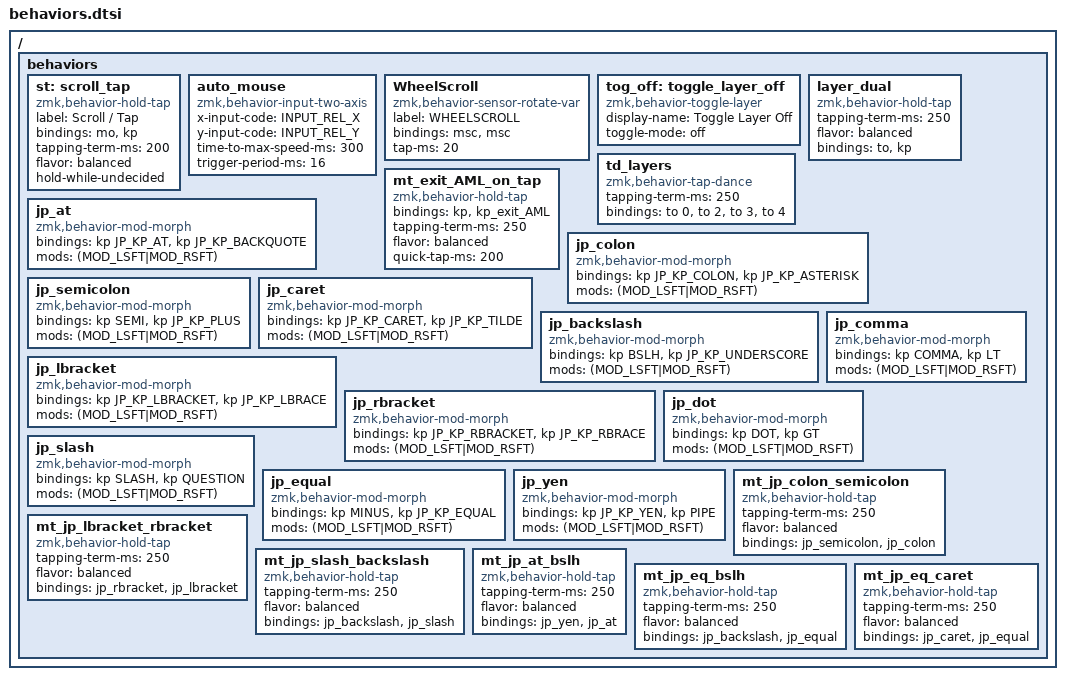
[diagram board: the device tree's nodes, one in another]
#include "JP_KP_defines.h"

/ {
    behaviors {
        st: scroll_tap {
            compatible = "zmk,behavior-hold-tap";
            label = "Scroll / Tap";
            bindings = <&mo>, <&kp>;

            #binding-cells = <2>;
            tapping-term-ms = <200>;
            flavor = "balanced";
            hold-while-undecided;
        };

        auto_mouse: auto_mouse {
            compatible = "zmk,behavior-input-two-axis";
            #binding-cells = <1>;
            x-input-code = <INPUT_REL_X>;
            y-input-code = <INPUT_REL_Y>;
            time-to-max-speed-ms = <300>;
            trigger-period-ms = <16>;
        };

        WheelScroll: WheelScroll {
            compatible = "zmk,behavior-sensor-rotate-var";
            label = "WHEELSCROLL";
            #sensor-binding-cells = <2>;
            bindings = <&msc>, <&msc>;

            tap-ms = <20>;
        };

        tog_off: toggle_layer_off {
            compatible = "zmk,behavior-toggle-layer";
            #binding-cells = <1>;
            display-name = "Toggle Layer Off";
            toggle-mode = "off";
        };

        layer_dual: layer_dual {
            compatible = "zmk,behavior-hold-tap";
            #binding-cells = <2>;
            tapping-term-ms = <250>;
            flavor = "balanced";
            bindings = <&to>, <&kp>;
        };

        //        td_layer2_3: tap_dance_combo {
        //            compatible = "zmk,behavior-tap-dance";
        //            #binding-cells = <0>;
        //            tapping-term-ms = <250>;
        //            bindings = <&layer_dual 0 2>, <&to 3>;
        //        };

        td_layers: td_layers {
            compatible = "zmk,behavior-tap-dance";
            #binding-cells = <0>;
            tapping-term-ms = <250>;
            bindings = <&to 0>, <&to 2>, <&to 3>, <&to 4>;

            //    bindings = <&kp A>, <&kp B>, <&kp C>;
        };

        mt_exit_AML_on_tap: mt_exit_AML_on_tap {
            compatible = "zmk,behavior-hold-tap";
            bindings = <&kp &kp_exit_AML>;
            #binding-cells = <2>;
            tapping-term-ms = <250>;
            flavor = "balanced";
            quick-tap-ms = <200>;
        };

        // @（通常） / `（Shift）

        jp_at: jp_at {
            compatible = "zmk,behavior-mod-morph";
            #binding-cells = <0>;
            bindings = <&kp JP_KP_AT &kp JP_KP_BACKQUOTE>;
            mods = <(MOD_LSFT|MOD_RSFT)>;
        };

        // :（通常） / *（Shift）

        jp_colon: jp_colon {
            compatible = "zmk,behavior-mod-morph";
            #binding-cells = <0>;
            bindings = <&kp JP_KP_COLON &kp JP_KP_ASTERISK>;
            mods = <(MOD_LSFT|MOD_RSFT)>;
        };

        // ;（通常） / +（Shift）

        jp_semicolon: jp_semicolon {
            compatible = "zmk,behavior-mod-morph";
            #binding-cells = <0>;
            bindings = <&kp SEMI &kp JP_KP_PLUS>;
            mods = <(MOD_LSFT|MOD_RSFT)>;
        };

        // ^（通常） / ~（Shift）

        jp_caret: jp_caret {
            compatible = "zmk,behavior-mod-morph";
            #binding-cells = <0>;
            bindings = <&kp JP_KP_CARET &kp JP_KP_TILDE>;
            mods = <(MOD_LSFT|MOD_RSFT)>;
        };

        // \（通常） / _（Shift）

        jp_backslash: jp_backslash {
            compatible = "zmk,behavior-mod-morph";
            #binding-cells = <0>;
            bindings = <&kp BSLH &kp JP_KP_UNDERSCORE>;
            mods = <(MOD_LSFT|MOD_RSFT)>;
        };

        // [（通常） / {（Shift）

        jp_lbracket: jp_lbracket {
            compatible = "zmk,behavior-mod-morph";
            #binding-cells = <0>;
            bindings = <&kp JP_KP_LBRACKET &kp JP_KP_LBRACE>;
            mods = <(MOD_LSFT|MOD_RSFT)>;
        };

        // ]（通常） / }（Shift）

        jp_rbracket: jp_rbracket {
            compatible = "zmk,behavior-mod-morph";
            #binding-cells = <0>;
            bindings = <&kp JP_KP_RBRACKET &kp JP_KP_RBRACE>;
            mods = <(MOD_LSFT|MOD_RSFT)>;
        };

        // ,（通常） / <（Shift）

        jp_comma: jp_comma {
            compatible = "zmk,behavior-mod-morph";
            #binding-cells = <0>;
            bindings = <&kp COMMA &kp LT>;
            mods = <(MOD_LSFT|MOD_RSFT)>;
        };

        // .（通常） / >（Shift）

        jp_dot: jp_dot {
            compatible = "zmk,behavior-mod-morph";
            #binding-cells = <0>;
            bindings = <&kp DOT &kp GT>;
            mods = <(MOD_LSFT|MOD_RSFT)>;
        };

        // /（通常） / ?（Shift）

        jp_slash: jp_slash {
            compatible = "zmk,behavior-mod-morph";
            #binding-cells = <0>;
            bindings = <&kp SLASH &kp QUESTION>;
            mods = <(MOD_LSFT|MOD_RSFT)>;
        };

        jp_equal: jp_equal {
            compatible = "zmk,behavior-mod-morph";
            #binding-cells = <0>;
            bindings = <&kp MINUS &kp JP_KP_EQUAL>;
            mods = <(MOD_LSFT|MOD_RSFT)>;
        };

        jp_yen: jp_yen {
            compatible = "zmk,behavior-mod-morph";
            #binding-cells = <0>;
            bindings = <&kp JP_KP_YEN &kp PIPE>;
            mods = <(MOD_LSFT|MOD_RSFT)>;
        };

        mt_jp_colon_semicolon: mt_jp_colon_semicolon {
            compatible = "zmk,behavior-hold-tap";
            #binding-cells = <2>;
            tapping-term-ms = <250>;
            flavor = "balanced";   // ←重要
            bindings = <&jp_semicolon &jp_colon>;
        };

        mt_jp_lbracket_rbracket: mt_jp_lbracket_rbracket {
            compatible = "zmk,behavior-hold-tap";
            #binding-cells = <2>;
            tapping-term-ms = <250>;
            flavor = "balanced";   // ←重要
            bindings = <&jp_rbracket &jp_lbracket>;
        };

        mt_jp_slash_backslash: mt_jp_slash_backslash {
            compatible = "zmk,behavior-hold-tap";
            #binding-cells = <2>;
            tapping-term-ms = <250>;
            flavor = "balanced";   // ←重要
            bindings = <&jp_backslash &jp_slash>;
        };

        mt_jp_at_bslh: mt_jp_at_bslh {
            compatible = "zmk,behavior-hold-tap";
            #binding-cells = <2>;
            tapping-term-ms = <250>;
            flavor = "balanced";   // ←重要
            bindings = <&jp_yen &jp_at>;
        };

        mt_jp_eq_bslh: mt_jp_eq_bslh {
            compatible = "zmk,behavior-hold-tap";
            #binding-cells = <2>;
            tapping-term-ms = <250>;
            flavor = "balanced";   // ←重要
            bindings = <&jp_backslash &jp_equal>;
        };

        mt_jp_eq_caret: mt_jp_eq_caret {
            compatible = "zmk,behavior-hold-tap";
            #binding-cells = <2>;
            tapping-term-ms = <250>;
            flavor = "balanced";   // ←重要
            bindings = <&jp_caret &jp_equal>;
        };
    };
};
